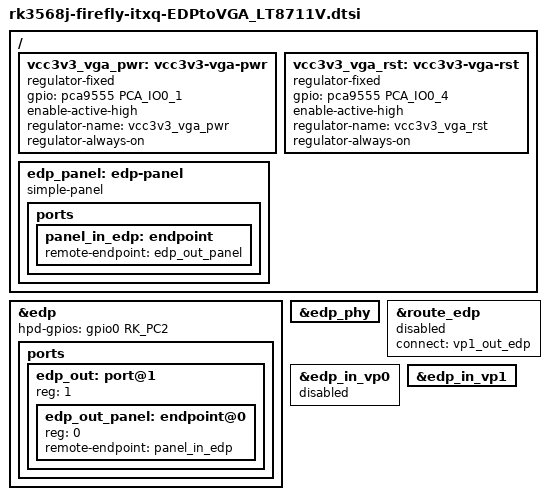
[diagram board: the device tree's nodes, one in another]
// SPDX-License-Identifier: (GPL-2.0+ OR MIT)
/*
 * Copyright (c) 2020 Rockchip Electronics Co., Ltd.
 * Support EDP to VGA LT8711V
 */

#include <dt-bindings/display/media-bus-format.h>

/ {
	vcc3v3_vga_pwr: vcc3v3-vga-pwr {
		compatible = "regulator-fixed";
		gpio =  <&pca9555 PCA_IO0_1 GPIO_ACTIVE_HIGH>;
		enable-active-high;
		regulator-name = "vcc3v3_vga_pwr";
		regulator-always-on;
	};

	vcc3v3_vga_rst: vcc3v3-vga-rst {
		compatible = "regulator-fixed";
		gpio =  <&pca9555 PCA_IO0_4 GPIO_ACTIVE_HIGH>;
		enable-active-high;
		regulator-name = "vcc3v3_vga_rst";
		regulator-always-on;
	};

    edp_panel: edp-panel {
		compatible = "simple-panel";
		status = "okay";
		/*
		display-timings {
           native-mode = <&timing0>;
           timing0: timing0 {
               clock-frequency = <148500000>;
               hactive = <1920>;
               vactive = <1080>;
               hfront-porch = <88>;
               hsync-len = <48>;
               hback-porch = <148>;
               vfront-porch = <4>;
               vsync-len = <5>;
               vback-porch = <36>;
               hsync-active = <0>;
               vsync-active = <0>;
               de-active = <0>;
               pixelclk-active = <0>;
           };
       };*/

		ports {
			panel_in_edp: endpoint {
				remote-endpoint = <&edp_out_panel>;
			};
		};
	};
};

&edp {
	status = "okay";
	hpd-gpios = <&gpio0 RK_PC2 GPIO_ACTIVE_HIGH>;
	//force-hpd;
	//enable-delay-ms = <200>; // vcc to hpd delay 900ms for power on sequence

	ports {
		edp_out: port@1 {
			reg = <1>;
			#address-cells = <1>;
			#size-cells = <0>;

			edp_out_panel: endpoint@0 {
				reg = <0>;
				remote-endpoint = <&panel_in_edp>;
			};
		};
	};
};

&edp_phy {
	status = "okay";
};

&route_edp {
	status = "disabled";
	connect = <&vp1_out_edp>;
};

&edp_in_vp0 {
	status = "disabled";
};

&edp_in_vp1 {
	status = "okay";
};
